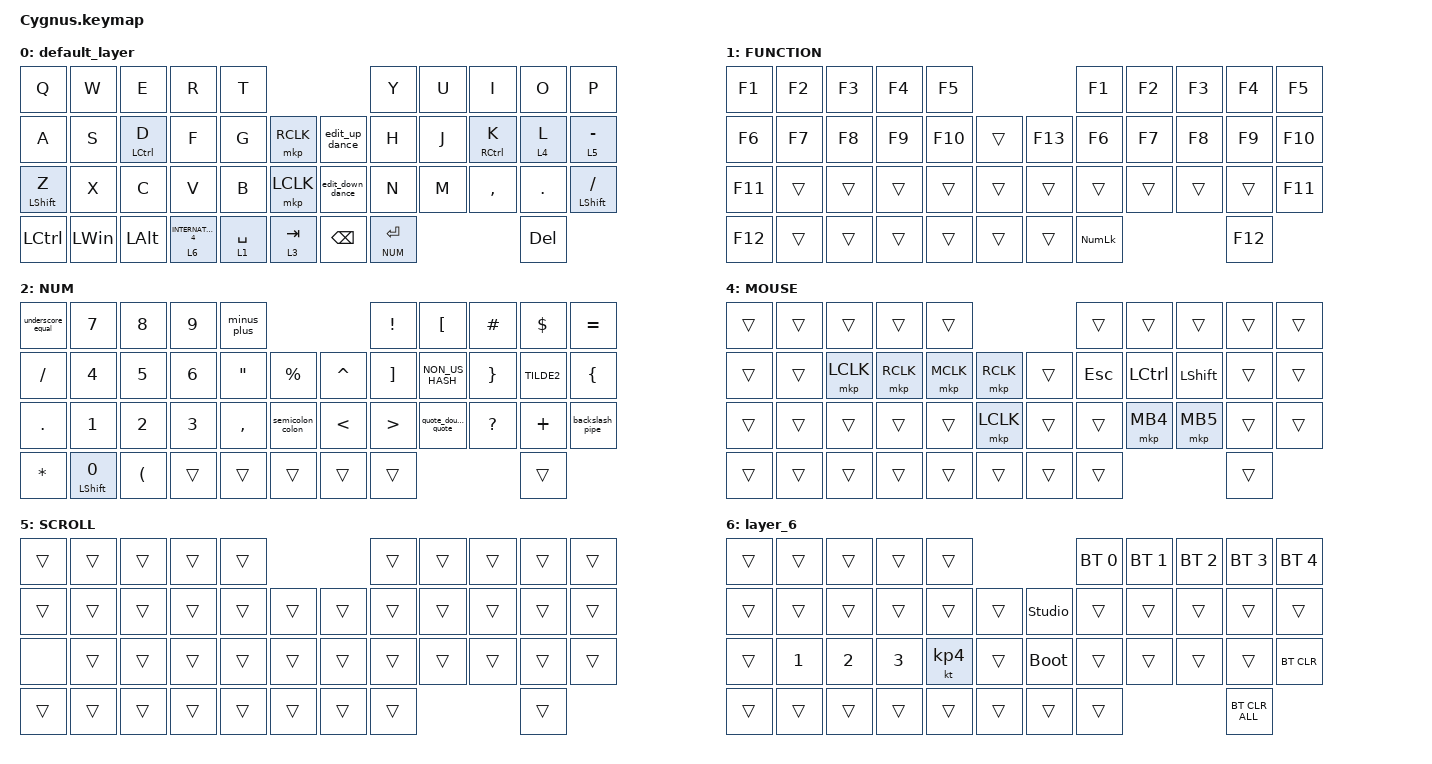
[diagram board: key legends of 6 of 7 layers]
#define ZMK_POINTING_DEFAULT_SCRL_VAL 120    // default: 10

#include <behaviors.dtsi>
#include <dt-bindings/zmk/bt.h>
#include <dt-bindings/zmk/keys.h>
#include <dt-bindings/zmk/modifiers.h>
#include <dt-bindings/zmk/pointing.h>

#define MOUSE 4
#define SCROLL 5
#define NUM 2

&mt {
    flavor = "balanced";
    tapping-term-ms = <150>;
    quick-tap-ms = <0>;
};

/ {
    combos {
        compatible = "zmk,combos";

        double_quotation {
            bindings = <&kp DOUBLE_QUOTES>;
            key-positions = <20 21>;
        };
    };

    macros {
        to_layer_0: to_layer_0 {
            compatible = "zmk,behavior-macro-one-param";
            #binding-cells = <1>;
            bindings = <&to 0 &macro_param_1to1 &kp MACRO_PLACEHOLDER>;
            label = "TO_LAYER_0";
        };

        /*
         * Windows Alt+0095
         * アンダースコア "_"
         * NumLockオンが必要。
         */
        und: und {
            compatible = "zmk,behavior-macro";
            #binding-cells = <0>;
            label = "UND";
            wait-ms = <40>;
            tap-ms = <40>;

            bindings
                = <&macro_press &kp LEFT_ALT>
                , <&macro_tap
                    &kp KP_NUMBER_0
                    &kp KP_NUMBER_0
                    &kp KP_NUMBER_9
                    &kp KP_NUMBER_5>
                , <&macro_release &kp LEFT_ALT>
                ;
        };

        /*
         * Windows Alt+0092
         * バックスラッシュ "\"
         * NumLockオンが必要。
         */
        bsl: bsl {
            compatible = "zmk,behavior-macro";
            #binding-cells = <0>;
            label = "BSL";
            wait-ms = <40>;
            tap-ms = <40>;

            bindings
                = <&macro_press &kp LEFT_ALT>
                , <&macro_tap
                    &kp KP_NUMBER_0
                    &kp KP_NUMBER_0
                    &kp KP_NUMBER_9
                    &kp KP_NUMBER_2>
                , <&macro_release &kp LEFT_ALT>
                ;
        };

        /*
         * Windows Alt+0124
         * パイプ "|"
         * NumLockオンが必要。
         */
        pipe: pipe {
            compatible = "zmk,behavior-macro";
            #binding-cells = <0>;
            label = "PIPE";
            wait-ms = <40>;
            tap-ms = <40>;

            bindings
                = <&macro_press &kp LEFT_ALT>
                , <&macro_tap
                    &kp KP_NUMBER_0
                    &kp KP_NUMBER_1
                    &kp KP_NUMBER_2
                    &kp KP_NUMBER_4>
                , <&macro_release &kp LEFT_ALT>
                ;
        };
    };

    behaviors {
        lt_to_layer_0: lt_to_layer_0 {
            compatible = "zmk,behavior-hold-tap";
            label = "LAYER_TAP_TO_0";
            bindings = <&mo>, <&to_layer_0>;

            #binding-cells = <2>;
            tapping-term-ms = <200>;
        };

        /*
         * Enter短押し：Enter
         * Enter長押し：NUMレイヤー
         *
         * Shiftを保持した場合も同じ判定を行う。
         * IME状態は変更しない。
         */
        num_enter: num_enter {
            compatible = "zmk,behavior-hold-tap";
            label = "NUM_ENTER";
            bindings = <&mo>, <&kp>;

            #binding-cells = <2>;
            flavor = "tap-preferred";
            tapping-term-ms = <150>;
            quick-tap-ms = <0>;
        };

        edit_up: edit_up {
            compatible = "zmk,behavior-hold-tap";
            label = "EDIT_UP";
            bindings = <&kp>, <&kp>;

            #binding-cells = <2>;
            flavor = "tap-preferred";
            tapping-term-ms = <200>;
            quick-tap-ms = <0>;
        };

        /*
         * 単押し：Ctrl+C
         * 長押し：Ctrl+X
         * 2回押し：Ctrl+Z
         */
        edit_up_dance: edit_up_dance {
            compatible = "zmk,behavior-tap-dance";
            label = "EDIT_UP_DANCE";
            #binding-cells = <0>;
            tapping-term-ms = <200>;

            bindings =
                <&edit_up LC(X) LC(C)>,
                <&kp LC(Z)>;
        };

        edit_down: edit_down {
            compatible = "zmk,behavior-hold-tap";
            label = "EDIT_DOWN";
            bindings = <&kp>, <&kp>;

            #binding-cells = <2>;
            flavor = "tap-preferred";
            tapping-term-ms = <200>;
            quick-tap-ms = <0>;
        };

        /*
         * 単押し：Ctrl+V
         * 長押し：Ctrl+Shift+V
         * 2回押し：Ctrl+Shift+Z
         */
        edit_down_dance: edit_down_dance {
            compatible = "zmk,behavior-tap-dance";
            label = "EDIT_DOWN_DANCE";
            #binding-cells = <0>;
            tapping-term-ms = <200>;

            bindings =
                <&edit_down LC(LS(V)) LC(V)>,
                <&kp LC(LS(Z))>;
        };

        /*
         * 単押し：_
         * Shift併用：=
         */
        underscore_equal: underscore_equal {
            compatible = "zmk,behavior-mod-morph";
            label = "UND_EQ";
            #binding-cells = <0>;

            bindings = <&und>, <&kp LS(MINUS)>;
            mods = <(MOD_LSFT | MOD_RSFT)>;
        };

        /*
         * 単押し：-
         * Shift併用：+
         */
        minus_plus: minus_plus {
            compatible = "zmk,behavior-mod-morph";
            label = "MIN_PLUS";
            #binding-cells = <0>;

            bindings = <&kp MINUS>, <&kp LS(SEMICOLON)>;
            mods = <(MOD_LSFT | MOD_RSFT)>;
        };

        /*
         * 単押し：;
         * Shift併用：:
         */
        semicolon_colon: semicolon_colon {
            compatible = "zmk,behavior-mod-morph";
            label = "SEMI_COL";
            #binding-cells = <0>;

            bindings = <&kp SEMICOLON>, <&kp SINGLE_QUOTE>;
            mods = <(MOD_LSFT | MOD_RSFT)>;
        };

        /*
         * 単押し：'
         * Shift併用："
         */
        quote_double_quote: quote_double_quote {
            compatible = "zmk,behavior-mod-morph";
            label = "QUOTE_DQ";
            #binding-cells = <0>;

            bindings = <&kp LS(NUMBER_7)>, <&kp LS(NUMBER_2)>;
            mods = <(MOD_LSFT | MOD_RSFT)>;
        };

        /*
         * 単押し：\
         * Shift併用：|
         */
        backslash_pipe: backslash_pipe {
            compatible = "zmk,behavior-mod-morph";
            label = "BSL_PIPE";
            #binding-cells = <0>;

            bindings = <&bsl>, <&pipe>;
            mods = <(MOD_LSFT | MOD_RSFT)>;
        };

        ROTATE: ROTATE {
            compatible = "zmk,behavior-sensor-rotate-var";
            label = "ROTATE";
            #sensor-binding-cells = <2>;
            bindings = <&msc>, <&msc>;

            tap-ms = <20>;
        };
    };

    keymap {
        compatible = "zmk,keymap";

        default_layer {
            bindings = <
&kp Q             &kp W         &kp E                  &kp R                  &kp T                                                   &kp Y              &kp U  &kp I      &kp O    &kp P
&kp A             &kp S         &mt LEFT_CONTROL D     &kp F                  &kp G        &mkp RCLK                  &edit_up_dance       &kp H              &kp J  &mt RIGHT_CONTROL K  &lt 4 L  &lt 5 MINUS
&mt LEFT_SHIFT Z  &kp X         &kp C                  &kp V                  &kp B        &mkp LCLK                  &edit_down_dance     &kp N              &kp M  &kp COMMA           &kp DOT  &mt LEFT_SHIFT SLASH
&kp LCTRL         &kp LEFT_WIN  &kp LEFT_ALT           &lt 6 INTERNATIONAL_4  &lt 1 SPACE  &lt 3 TAB      &kp BACKSPACE        &num_enter NUM ENTER                               &kp DEL
            >;

            sensor-bindings = <&ROTATE SCRL_DOWN SCRL_UP>;
        };

        /*
         * Space長押しで呼び出すFUNCTIONレイヤー
         *
         * 右親指のEnter位置：
         * NumLockオン／オフ
         */
        FUNCTION {
            bindings = <
&kp F1   &kp F2  &kp F3  &kp F4  &kp F5                        &kp F1  &kp F2  &kp F3  &kp F4  &kp F5
&kp F6   &kp F7  &kp F8  &kp F9  &kp F10  &trans      &kp F13  &kp F6  &kp F7  &kp F8  &kp F9  &kp F10
&kp F11  &trans  &trans  &trans  &trans   &trans      &trans   &trans  &trans  &trans  &trans  &kp F11
&kp F12  &trans  &trans  &trans  &trans   &trans      &trans   &kp KP_NUMLOCK                  &kp F12
            >;
        };

        /*
         * Enter長押しで呼び出すNUMレイヤー
         *
         * IME状態は変更しない。
         *
         * Shiftを保持してNUMを呼び出すと、
         * Mod-Morphキーの第2記号を入力する。
         *
         * _/=   7     8     9     -/+       !     @     #     $     ^
         * /     4     5     6     *    %    &     [     ]     {     }     `
         * .     1     2     3     ,    ;/:  <     >     '/"   ?     ~     \ / |
         * (     0     )
         *
         * 0：
         * 単押し 0／長押し Shift
         */
        NUM {
            bindings = <
&underscore_equal  &kp NUMBER_7             &kp NUMBER_8            &kp NUMBER_9             &minus_plus                                      &kp EXCLAMATION  &kp LEFT_BRACKET   &kp HASH           &kp DOLLAR          &kp EQUAL
&kp SLASH          &kp NUMBER_4             &kp NUMBER_5            &kp NUMBER_6             &kp DOUBLE_QUOTES  &kp PERCENT          &kp CARET        &kp RIGHT_BRACKET  &kp NON_US_HASH    &kp RIGHT_BRACE     &kp TILDE2  &kp LEFT_BRACE
&kp PERIOD         &kp NUMBER_1             &kp NUMBER_2            &kp NUMBER_3             &kp COMMA          &semicolon_colon      &kp LESS_THAN    &kp GREATER_THAN   &quote_double_quote &kp QUESTION        &kp PLUS    &backslash_pipe
&kp ASTERISK       &mt LEFT_SHIFT NUMBER_0  &kp LEFT_PARENTHESIS    &trans                   &trans             &trans                &trans           &trans              &trans
            >;
        };

        /*
         * カーソル・文書移動レイヤー
         */
        ARROW {
            bindings = <
&kp ESCAPE    &kp LC(LS(TAB))     &kp UP_ARROW    &kp LC(TAB)          &trans                        &trans  &trans  &trans  &trans  &trans
&kp HOME      &kp LEFT_ARROW      &kp DOWN_ARROW  &kp RIGHT_ARROW      &kp END  &trans      &trans  &trans  &trans  &trans  &trans
&kp LC(HOME)  &kp LC(LEFT_ARROW)  &kp LEFT_SHIFT  &kp LC(RIGHT_ARROW)  &kp LC(END)  &trans  &trans  &trans  &trans  &trans  &trans  &trans
&trans        &trans              &trans          &trans               &trans       &trans  &trans  &trans                          &trans
            >;

            sensor-bindings = <&inc_dec_kp LC(PAGE_UP) LC(PAGE_DOWN)>;
        };

        MOUSE {
            bindings = <
&trans  &trans  &trans     &trans     &trans                              &trans            &trans            &trans             &trans  &trans
&trans  &trans  &mkp LCLK  &mkp RCLK  &mkp MCLK  &mkp RCLK      &trans    &kp ESCAPE        &kp LEFT_CONTROL  &kp LEFT_SHIFT     &trans  &trans
&trans  &trans  &trans     &trans     &trans     &mkp LCLK      &trans    &trans            &mkp MB4          &mkp MB5           &trans  &trans
&trans  &trans  &trans     &trans     &trans     &trans         &trans    &trans                                                   &trans
            >;
        };

        SCROLL {
            bindings = <
&trans  &trans  &trans  &trans  &trans                      &trans  &trans  &trans  &trans  &trans
&trans  &trans  &trans  &trans  &trans  &trans      &trans  &trans  &trans  &trans  &trans  &trans
&none   &trans  &trans  &trans  &trans  &trans      &trans  &trans  &trans  &trans  &trans  &trans
&trans  &trans  &trans  &trans  &trans  &trans      &trans  &trans                          &trans
            >;
        };

        layer_6 {
            bindings = <
&trans  &trans        &trans        &trans        &trans                                 &bt BT_SEL 0  &bt BT_SEL 1  &bt BT_SEL 2  &bt BT_SEL 3  &bt BT_SEL 4
&trans  &trans        &trans        &trans        &trans     &trans      &studio_unlock  &trans        &trans        &trans        &trans        &trans
&trans  &kp NUMBER_1  &kp NUMBER_2  &kp NUMBER_3  &kt KP_N4  &trans      &bootloader     &trans        &trans        &trans        &trans        &bt BT_CLR
&trans  &trans        &trans        &trans        &trans     &trans      &trans          &trans                                                  &bt BT_CLR_ALL
            >;
        };
    };
};
